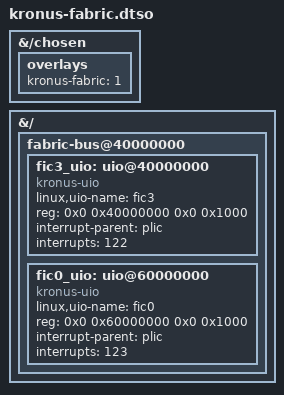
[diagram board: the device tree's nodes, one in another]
/dts-v1/;
/plugin/;

&{/chosen} {
	overlays {
		kronus-fabric = "1";
	};
};

&{/} {
	fabric-bus@40000000 {
		fic3_uio: uio@40000000 {
			compatible = "kronus-uio";
			linux,uio-name = "fic3";
			reg = <0x0 0x40000000 0x0 0x1000>;
			interrupt-parent = <&plic>;
			interrupts = <122>;
			status = "okay";
		};

		fic0_uio: uio@60000000 {
			compatible = "kronus-uio";
			linux,uio-name = "fic0";
			reg = <0x0 0x60000000 0x0 0x1000>;
			interrupt-parent = <&plic>;
			interrupts = <123>;
			status = "okay";
		};
	};
};
